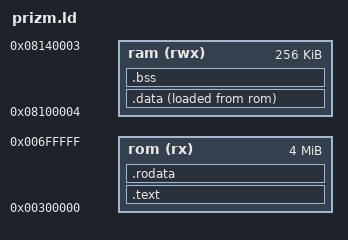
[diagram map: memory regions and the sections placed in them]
OUTPUT_FORMAT(binary) 
OUTPUT_ARCH(sh3)
 
/* Entry point.  Not really important here, since doing binary output */
ENTRY(initialize)
 
MEMORY
{
        /* Loads code at 300000, skips g3a header */
        rom (rx) : o = 0x00300000, l = 4096k
        ram (rwx) : o = 0x08100004, l = 256k  /* pretty safe guess */
}
 
SECTIONS
{
        /* Code, in ROM */
        .text : {
                *(.pretext)     /* init stuff */
                *(.text)
                *(.text.*)
        } > rom
       
        /* Read-only data, in ROM */
        .rodata : {
                *(.rodata)
                *(.rodata.*)
        } > rom
       
        /* RW initialized data, VMA in RAM but LMA in ROM */
        .data : {
                _datald = LOADADDR(.data) ;
                _sdata = . ;
                *(.data)
                *(.data.*);
                _edata = . ;
        } >ram AT>rom
       
        /* Uninitialized data (fill with 0), in RAM */
        .bss : {
                _bbss = . ;
                *(.bss) *(COMMON);
                _ebss = . ;
        } >ram
}
